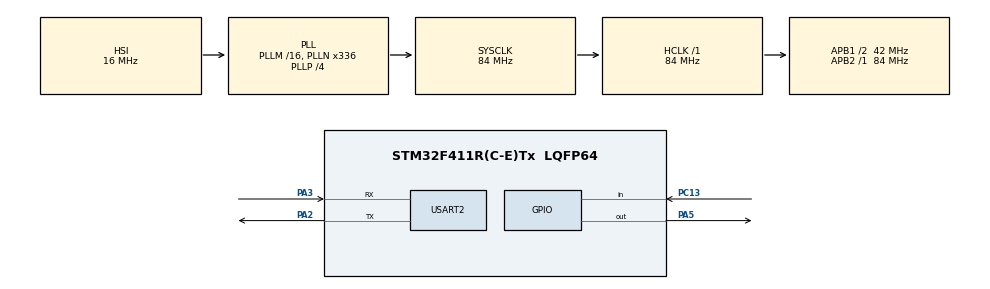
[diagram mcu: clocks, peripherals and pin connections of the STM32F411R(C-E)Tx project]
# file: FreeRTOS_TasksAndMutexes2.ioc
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FREERTOS.Mutexes01=uart_mutex,Dynamic,NULL,Available
FREERTOS.Tasks01=defaultTask,0,128,StartDefaultTask,Default,NULL,Dynamic,NULL,NULL;Thread1,-3,128,Thread1Func,Default,NULL,Dynamic,NULL,NULL;Thread2,-3,128,Thread2Func,Default,NULL,Dynamic,NULL,NULL
FREERTOS.configUSE_NEWLIB_REENTRANT=1
Mcu.Family=STM32F4
Mcu.Name=STM32F411R(C-E)Tx
Mcu.Package=LQFP64
NVIC.PriorityGroup=NVIC_PRIORITYGROUP_4
NVIC.TIM3_IRQn=true\:15\:0\:false\:false\:true\:false\:false\:true\:true
NVIC.TimeBase=TIM3_IRQn
NVIC.TimeBaseIP=TIM3
PA13.Mode=Serial_Wire
PA13.Signal=SYS_JTMS-SWDIO
PA14.Mode=Serial_Wire
PA14.Signal=SYS_JTCK-SWCLK
PA2.Mode=Asynchronous
PA2.Signal=USART2_TX
PA3.Mode=Asynchronous
PA3.Signal=USART2_RX
PA5.Signal=GPIO_Output
PC13-ANTI_TAMP.Signal=GPIO_Input
ProjectManager.HeapSize=0x200
ProjectManager.StackSize=0x400
ProjectManager.TargetToolchain=STM32CubeIDE
RCC.48MHZClocksFreq_Value=84000000
RCC.AHBFreq_Value=84000000
RCC.APB1CLKDivider=RCC_HCLK_DIV2
RCC.APB1Freq_Value=42000000
RCC.APB1TimFreq_Value=84000000
RCC.APB2Freq_Value=84000000
RCC.APB2TimFreq_Value=84000000
RCC.CortexFreq_Value=84000000
RCC.FLatency-AdvancedSettings=FLASH_LATENCY_2
RCC.HCLKFreq_Value=84000000
RCC.HSE_VALUE=8000000
RCC.HSI_VALUE=16000000
RCC.LSE_VALUE=32768
RCC.PLLN=336
RCC.PLLP=RCC_PLLP_DIV4
RCC.SYSCLKFreq_VALUE=84000000
RCC.SYSCLKSource=RCC_SYSCLKSOURCE_PLLCLK
RCC.VCOOutputFreq_Value=336000000
USART2.VirtualMode=VM_ASYNC
VP_FREERTOS_VS_CMSIS_V1.Mode=CMSIS_V1
VP_SYS_VS_tim3.Mode=TIM3
board=NUCLEO-F411RE

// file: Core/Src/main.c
/* USER CODE BEGIN Header */
/**
  ******************************************************************************
  * @file           : main.c
  * @brief          : Main program body
  ******************************************************************************
  * @attention
  *
  * Copyright (c) 2025 STMicroelectronics.
  * All rights reserved.
  *
  * This software is licensed under terms that can be found in the LICENSE file
  * in the root directory of this software component.
  * If no LICENSE file comes with this software, it is provided AS-IS.
  *
  ******************************************************************************
  */
/* USER CODE END Header */
#include "main.h"
#include "cmsis_os.h"

UART_HandleTypeDef huart2;

osThreadId defaultTaskHandle;
osThreadId Thread1Handle;
osThreadId Thread2Handle;
osMutexId uart_mutexHandle;

typedef  uint32_t  TaskProfiler;

TaskProfiler Thread_1_Profiler,Thread_2_Profiler,Default_Thread_Profiler;

void SystemClock_Config(void);
static void MX_GPIO_Init(void);
static void MX_USART2_UART_Init(void);
void StartDefaultTask(void const * argument);
void Thread1Func(void const * argument);
void Thread2Func(void const * argument);

int main(void)
{

  HAL_Init();

  SystemClock_Config();

  MX_GPIO_Init();
  MX_USART2_UART_Init();

  osMutexDef(uart_mutex);
  uart_mutexHandle = osMutexCreate(osMutex(uart_mutex));

  /* Create the thread(s) */
  /* definition and creation of defaultTask */
  osThreadDef(defaultTask, StartDefaultTask, osPriorityNormal, 0, 128);
  defaultTaskHandle = osThreadCreate(osThread(defaultTask), NULL);

  /* definition and creation of Thread1 */
  osThreadDef(Thread1, Thread1Func, osPriorityNormal, 0, 128);
  Thread1Handle = osThreadCreate(osThread(Thread1), NULL);

  /* definition and creation of Thread2 */
  osThreadDef(Thread2, Thread2Func, osPriorityNormal, 0, 128);
  Thread2Handle = osThreadCreate(osThread(Thread2), NULL);

  osKernelStart();

  while (1)
  {

  }

}

void SystemClock_Config(void)
{
  RCC_OscInitTypeDef RCC_OscInitStruct = {0};
  RCC_ClkInitTypeDef RCC_ClkInitStruct = {0};

  /** Configure the main internal regulator output voltage
  */
  __HAL_RCC_PWR_CLK_ENABLE();
  __HAL_PWR_VOLTAGESCALING_CONFIG(PWR_REGULATOR_VOLTAGE_SCALE1);

  /** Initializes the RCC Oscillators according to the specified parameters
  * in the RCC_OscInitTypeDef structure.
  */
  RCC_OscInitStruct.OscillatorType = RCC_OSCILLATORTYPE_HSI;
  RCC_OscInitStruct.HSIState = RCC_HSI_ON;
  RCC_OscInitStruct.HSICalibrationValue = RCC_HSICALIBRATION_DEFAULT;
  RCC_OscInitStruct.PLL.PLLState = RCC_PLL_ON;
  RCC_OscInitStruct.PLL.PLLSource = RCC_PLLSOURCE_HSI;
  RCC_OscInitStruct.PLL.PLLM = 16;
  RCC_OscInitStruct.PLL.PLLN = 336;
  RCC_OscInitStruct.PLL.PLLP = RCC_PLLP_DIV4;
  RCC_OscInitStruct.PLL.PLLQ = 4;
  if (HAL_RCC_OscConfig(&RCC_OscInitStruct) != HAL_OK)
  {
    Error_Handler();
  }

  /** Initializes the CPU, AHB and APB buses clocks
  */
  RCC_ClkInitStruct.ClockType = RCC_CLOCKTYPE_HCLK|RCC_CLOCKTYPE_SYSCLK
                              |RCC_CLOCKTYPE_PCLK1|RCC_CLOCKTYPE_PCLK2;
  RCC_ClkInitStruct.SYSCLKSource = RCC_SYSCLKSOURCE_PLLCLK;
  RCC_ClkInitStruct.AHBCLKDivider = RCC_SYSCLK_DIV1;
  RCC_ClkInitStruct.APB1CLKDivider = RCC_HCLK_DIV2;
  RCC_ClkInitStruct.APB2CLKDivider = RCC_HCLK_DIV1;

  if (HAL_RCC_ClockConfig(&RCC_ClkInitStruct, FLASH_LATENCY_2) != HAL_OK)
  {
    Error_Handler();
  }
}

static void MX_USART2_UART_Init(void)
{

  huart2.Instance = USART2;
  huart2.Init.BaudRate = 115200;
  huart2.Init.WordLength = UART_WORDLENGTH_8B;
  huart2.Init.StopBits = UART_STOPBITS_1;
  huart2.Init.Parity = UART_PARITY_NONE;
  huart2.Init.Mode = UART_MODE_TX_RX;
  huart2.Init.HwFlowCtl = UART_HWCONTROL_NONE;
  huart2.Init.OverSampling = UART_OVERSAMPLING_16;
  if (HAL_UART_Init(&huart2) != HAL_OK)
  {
    Error_Handler();
  }

}

static void MX_GPIO_Init(void)
{
  GPIO_InitTypeDef GPIO_InitStruct = {0};

  /* GPIO Ports Clock Enable */
  __HAL_RCC_GPIOC_CLK_ENABLE();
  __HAL_RCC_GPIOA_CLK_ENABLE();

  /*Configure GPIO pin Output Level */
  HAL_GPIO_WritePin(GPIOA, GPIO_PIN_5, GPIO_PIN_RESET);

  /*Configure GPIO pin : PC13 */
  GPIO_InitStruct.Pin = GPIO_PIN_13;
  GPIO_InitStruct.Mode = GPIO_MODE_INPUT;
  GPIO_InitStruct.Pull = GPIO_NOPULL;
  HAL_GPIO_Init(GPIOC, &GPIO_InitStruct);

  /*Configure GPIO pin : PA5 */
  GPIO_InitStruct.Pin = GPIO_PIN_5;
  GPIO_InitStruct.Mode = GPIO_MODE_OUTPUT_PP;
  GPIO_InitStruct.Pull = GPIO_NOPULL;
  GPIO_InitStruct.Speed = GPIO_SPEED_FREQ_LOW;
  HAL_GPIO_Init(GPIOA, &GPIO_InitStruct);

}

/* USER CODE END Header_StartDefaultTask */
void StartDefaultTask(void const * argument)
{
  for(;;)
  {
    osDelay(1);
  }
}

void Thread1Func(void const * argument)
{
  /* USER CODE BEGIN Thread1Func */
  /* Infinite loop */
  uint8_t message[24] = "Greetings from Thread1\r\n";
  for(;;)
  {
	xSemaphoreTake(uart_mutexHandle,portMAX_DELAY);
	HAL_UART_Transmit(&huart2,message,24,10);
	xSemaphoreGive(uart_mutexHandle);
    osDelay(10);
  }
  /* USER CODE END Thread1Func */
}

/* USER CODE END Header_Thread2Func */
void Thread2Func(void const * argument)
{
  /* USER CODE BEGIN Thread2Func */
  /* Infinite loop */
	uint8_t message[24]="Greetings from Thread2\r\n";

  for(;;)
  {
	xSemaphoreTake(uart_mutexHandle,portMAX_DELAY);
	HAL_UART_Transmit(&huart2,message,24,10);
	xSemaphoreGive(uart_mutexHandle);
    osDelay(10);
  }
  /* USER CODE END Thread2Func */
}

void HAL_TIM_PeriodElapsedCallback(TIM_HandleTypeDef *htim)
{
  if (htim->Instance == TIM3)
  {
    HAL_IncTick();
  }
}

void Error_Handler(void)
{
  __disable_irq();
  while (1)
  {
  }
}
